# RSL15 register map
Vendor: ONSemiconductor; Series: RSL15 Series; File version: 1.0
CPU: CM33 r0p4, little endian, MPU, FPU, 3 interrupt priority bits
Registers are 32-bit, read-write, reset 0x0 unless marked. A register's access mark holds for its fields unless they carry their own. Offsets are from the block's base; [hi:lo] are bit positions; {n}, {i} and the like mark numbered series.

## PWM — PWM Interface
Base 0x40001100
{0x0+4i} PWM_PERIOD[{i}] (i=0..4)
  [11:0] PERIOD — PWM period
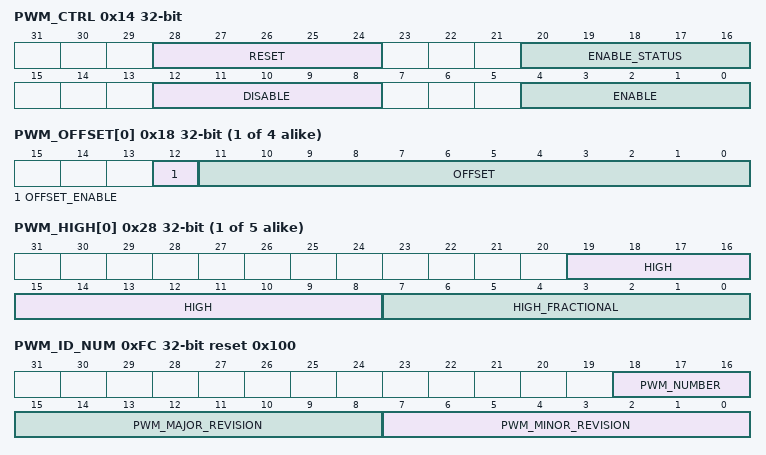
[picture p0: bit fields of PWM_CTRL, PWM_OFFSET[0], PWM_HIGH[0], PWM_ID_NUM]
0x14 PWM_CTRL (reset mask 0x1F0000) — PWM Control Register
  [28:24] RESET wo — PWM[4:0] channel reset
    1=PWM0_RESET (Disable the PWM0 channel, reset the PWM_CFG0 and PWM_OFFSET0 registers and the related counter.); 2=PWM1_RESET (Disable the PWM1 channel, reset the PWM_CFG1 and PWM_OFFSET1 registers and the related counter.); 4=PWM2_RESET (Disable the PWM2 channel, reset the PWM_CFG2 and PWM_OFFSET2 registers and the related counter.); 8=PWM3_RESET (Disable the PWM3 channel, reset the PWM_CFG3 and PWM_OFFSET3 registers and the related counter.); 16=PWM4_RESET (Disable the PWM4 channel, reset the PWM_CFG4 and PWM_OFFSET4 registers and the related counter.)
  [20:16] ENABLE_STATUS ro — PWM enable status
    0=PWM0_STATUS_DISABLE (PWM0 channel disable); 0=PWM1_STATUS_DISABLE (PWM1 channel disable); 0=PWM2_STATUS_DISABLE (PWM2 channel disable); 0=PWM3_STATUS_DISABLE (PWM3 channel disable); 0=PWM4_STATUS_DISABLE (PWM4 channel disable); 1=PWM0_STATUS_ENABLE (PWM0 channel enable); 2=PWM1_STATUS_ENABLE (PWM1 channel enable); 4=PWM2_STATUS_ENABLE (PWM2 channel enable); 8=PWM3_STATUS_ENABLE (PWM3 channel enable); 16=PWM4_STATUS_ENABLE (PWM4 channel enable)
  [12:8] DISABLE wo — Disable the PWM[4:0] channel
    1=PWM0_DISABLE (Disable the PWM0 channel); 2=PWM1_DISABLE (Disable the PWM1 channel); 4=PWM2_DISABLE (Disable the PWM2 channel); 8=PWM3_DISABLE (Disable the PWM3 channel); 16=PWM4_DISABLE (Disable the PWM4 channel)
  [4:0] ENABLE wo — Enable the PWM[4:0] channel
    1=PWM0_ENABLE (Enable the PWM0 channel); 2=PWM1_ENABLE (Enable the PWM1 channel); 4=PWM2_ENABLE (Enable the PWM2 channel); 8=PWM3_ENABLE (Enable the PWM3 channel); 16=PWM4_ENABLE (Enable the PWM4 channel)
{0x18+4i} PWM_OFFSET[{i}] (i=0..3)
  [12] OFFSET_ENABLE — Enable/disable the PWM offset function
    0=PWM_OFFSET_DISABLE (Disable the PWM offset); 1=PWM_OFFSET_ENABLE (Enable the PWM offset)
  [11:0] OFFSET — PWM(0) to PWM(i) offset
{0x28+4i} PWM_HIGH[{i}] (i=0..4) — PWM High configuration Register
  [19:8] HIGH — PWM high duration
  [7:0] HIGH_FRACTIONAL — PWM high fractional
0xFC PWM_ID_NUM ro reset 0x100 — PWM ID number
  [18:16] PWM_NUMBER — PWM number of channel
  [15:8] PWM_MAJOR_REVISION — PWM Major Revision number
    1=PWM_MAJOR_REVISION (PWM revision 1.0)
  [7:0] PWM_MINOR_REVISION — PWM Minor Revision number
    0=PWM_MINOR_REVISION (PWM revision 1.0)

## CRC — CRC Generator Control
Base 0x40001600
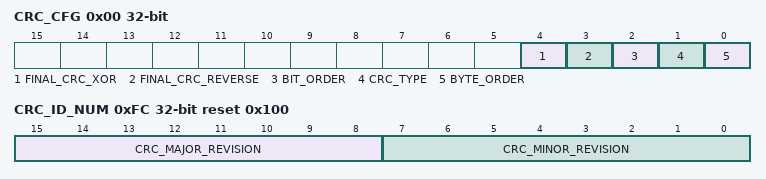
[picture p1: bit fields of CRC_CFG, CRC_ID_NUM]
0x00 CRC_CFG — CRC Generator Configuration Register
  [4] FINAL_CRC_XOR — Selects the final CRC XOR mode
    0=CRC_FINAL_XOR_STANDARD (Final CRC XOR is done according to the standard (CRC-CCITT: no XOR; CRC-32: XOR with 0xFFFFFFFF)); 1=CRC_FINAL_XOR_NON_STANDARD (Final CRC XOR is done in opposite of the standard)
  [3] FINAL_CRC_REVERSE — Selects the final CRC reversal mode
    0=CRC_FINAL_REVERSE_STANDARD (Final CRC reversal is done according to the standard (CRC-CCITT: normal; CRC-32 reversed)); 1=CRC_FINAL_REVERSE_NON_STANDARD (Final CRC reversal is done in opposite of the standard)
  [2] BIT_ORDER — Selects the bit order for bytes added to the CRC
    0=CRC_BIT_ORDER_STANDARD (Bit order is as defined by the standard (CRC-CCITT: normal; CRC-32 reversed)); 1=CRC_BIT_ORDER_NON_STANDARD (Bit order is opposite of the standard)
  [1] CRC_TYPE — Selects the CRC type
    0=CRC_CCITT (CRC-CCITT algorithm selected); 1=CRC_32 (CRC-32 (IEEE 802.3) algorithm selected)
  [0] BYTE_ORDER — Selects the endianness for bytes added to the CRC
    0=CRC_BIG_ENDIAN (Bytes are added to the CRC in big-endian order); 1=CRC_LITTLE_ENDIAN (Bytes are added to the CRC in little-endian order)
0x04 CRC_VALUE reset 0xFFFF — CRC Generator Current Value Register
  [31:0] CURRENT_CRC — CRC generator value: Write 0xFFFFFFF (32) or 0xFFFF (CCITT) to initialize the CRC, read provides the current CRC value.
    0xFFFF=CRC_CCITT_INIT_VALUE (Initial value for the CRC CCITT calculation); 0xFFFFFFFF=CRC_32_INIT_VALUE (Initial value for the CRC 32 calculation)
0x08 CRC_ADD_1 reset not defined — CRC Generator - Add 1 Bit
  [0] CRC_ADD_1 wo — Add 1 bit to the CRC calculation
0x0C CRC_ADD_8 reset not defined — CRC Generator - Add 1 Byte
  [7:0] CRC_ADD_8 wo — Add 1 byte (8 bits) to the CRC calculation
0x10 CRC_ADD_16 reset not defined — CRC Generator - Add 1 Half-word
  [15:0] CRC_ADD_16 wo — Add 1 half-word (16 bits) to the CRC calculation
0x14 CRC_ADD_24 reset not defined — CRC Generator - Add 3 Bytes
  [23:0] CRC_ADD_24 wo — Add 3 bytes (24 bits) to the CRC calculation
0x18 CRC_ADD_32 reset not defined — CRC Generator - Add 1 Word
  [31:0] CRC_ADD_32 wo — Add 1 word (32 bits) to the CRC calculation
0x1C CRC_FINAL ro — CRC Generator Final Value
  [31:0] FINAL_CRC — CRC generator final value: After XOR for CCITT or byte reversal for CRC-32
0xFC CRC_ID_NUM ro reset 0x100 — CRC ID number
  [15:8] CRC_MAJOR_REVISION — CRC Major Revision number
    1=CRC_MAJOR_REVISION (CRC revision 1.0)
  [7:0] CRC_MINOR_REVISION — CRC Minor Revision number
    0=CRC_MINOR_REVISION (CRC revision 1.0)
